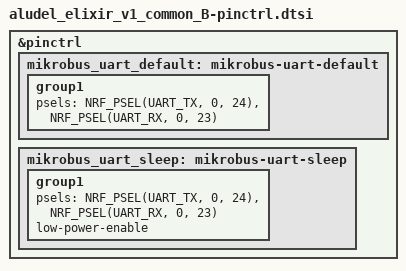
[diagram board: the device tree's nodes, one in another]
/*
 * Copyright (c) 2024 Golioth, Inc.
 *
 * SPDX-License-Identifier: Apache-2.0
 */

&pinctrl {
	/* UART pins connected to the mikroBUS headers */
	mikrobus_uart_default: mikrobus-uart-default {
		group1 {
			psels = <NRF_PSEL(UART_TX, 0, 24)>,
				<NRF_PSEL(UART_RX, 0, 23)>;
		};
	};

	mikrobus_uart_sleep: mikrobus-uart-sleep {
		group1 {
			psels = <NRF_PSEL(UART_TX, 0, 24)>,
				<NRF_PSEL(UART_RX, 0, 23)>;
			low-power-enable;
		};
	};
};
